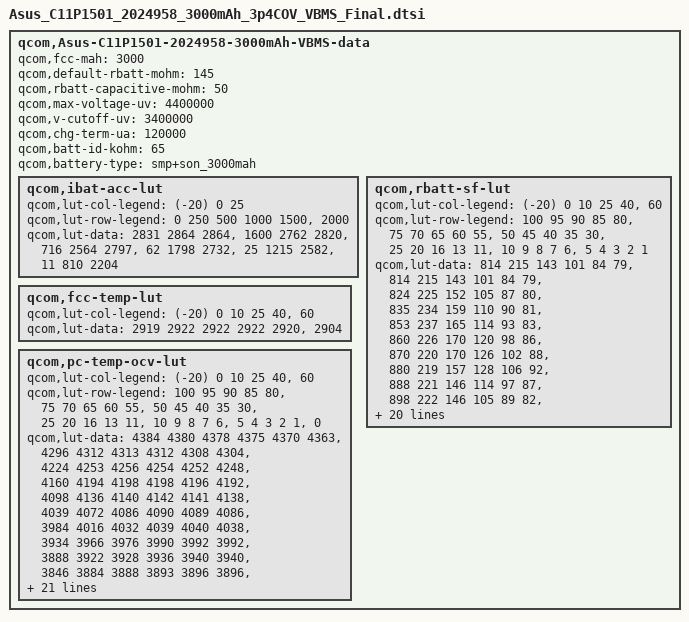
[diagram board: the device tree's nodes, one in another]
 qcom,Asus-C11P1501-2024958-3000mAh-VBMS-data {
	qcom,fcc-mah = <3000>;
	qcom,default-rbatt-mohm = <145>;
	qcom,rbatt-capacitive-mohm = <50>;
	qcom,max-voltage-uv = <4400000>;
	qcom,v-cutoff-uv = <3400000>;
	qcom,chg-term-ua = <120000>;
	qcom,batt-id-kohm = <65>;
	qcom,battery-type = "smp+son_3000mah";

	qcom,ibat-acc-lut {
		qcom,lut-col-legend = <(-20) 0 25>;
		qcom,lut-row-legend = <0 250 500 1000 1500>,
				<2000>;
		qcom,lut-data = <2831 2864 2864>,
				<1600 2762 2820>,
				<716 2564 2797>,
				<62 1798 2732>,
				<25 1215 2582>,
				<11 810 2204>;
	};

	qcom,rbatt-sf-lut {
		qcom,lut-col-legend = <(-20) 0 10 25 40>,
				<60>;
		qcom,lut-row-legend = <100 95 90 85 80>,
				<75 70 65 60 55>,
				<50 45 40 35 30>,
				<25 20 16 13 11>,
				<10 9 8 7 6>,
				<5 4 3 2 1>;
		qcom,lut-data = <814 215 143 101 84 79>,
				<814 215 143 101 84 79>,
				<824 225 152 105 87 80>,
				<835 234 159 110 90 81>,
				<853 237 165 114 93 83>,
				<860 226 170 120 98 86>,
				<870 220 170 126 102 88>,
				<880 219 157 128 106 92>,
				<888 221 146 114 97 87>,
				<898 222 146 105 89 82>,
				<919 226 149 103 88 81>,
				<953 230 152 107 90 82>,
				<1008 234 157 110 93 85>,
				<1088 243 160 114 96 87>,
				<1199 249 163 114 94 84>,
				<1356 255 166 110 91 82>,
				<1646 258 166 108 91 82>,
				<1948 258 161 109 90 83>,
				<2203 266 159 108 90 82>,
				<2425 284 163 109 91 83>,
				<2610 298 168 110 92 85>,
				<2849 313 174 113 94 88>,
				<2917 314 178 114 94 90>,
				<3444 324 183 117 95 91>,
				<5075 354 188 116 93 85>,
				<8561 406 192 113 92 85>,
				<16552 538 205 115 94 86>,
				<33105 989 243 121 97 88>,
				<63602 1978 328 130 102 91>,
				<100437 3956 657 157 126 106>;
	};

	qcom,fcc-temp-lut {
		qcom,lut-col-legend = <(-20) 0 10 25 40>,
				<60>;
		qcom,lut-data = <2919 2922 2922 2922 2920>,
				<2904>;
	};

	qcom,pc-temp-ocv-lut {
		qcom,lut-col-legend = <(-20) 0 10 25 40>,
				<60>;
		qcom,lut-row-legend = <100 95 90 85 80>,
				<75 70 65 60 55>,
				<50 45 40 35 30>,
				<25 20 16 13 11>,
				<10 9 8 7 6>,
				<5 4 3 2 1>,
				<0>;
		qcom,lut-data = <4384 4380 4378 4375 4370 4363>,
				<4296 4312 4313 4312 4308 4304>,
				<4224 4253 4256 4254 4252 4248>,
				<4160 4194 4198 4198 4196 4192>,
				<4098 4136 4140 4142 4141 4138>,
				<4039 4072 4086 4090 4089 4086>,
				<3984 4016 4032 4039 4040 4038>,
				<3934 3966 3976 3990 3992 3992>,
				<3888 3922 3928 3936 3940 3940>,
				<3846 3884 3888 3893 3896 3896>,
				<3809 3852 3856 3860 3862 3862>,
				<3779 3824 3830 3834 3836 3836>,
				<3755 3800 3806 3810 3814 3814>,
				<3736 3780 3786 3792 3794 3792>,
				<3718 3762 3768 3772 3770 3763>,
				<3702 3744 3750 3750 3744 3734>,
				<3686 3722 3728 3726 3720 3708>,
				<3670 3699 3704 3702 3696 3684>,
				<3654 3680 3684 3684 3678 3666>,
				<3638 3669 3672 3674 3670 3660>,
				<3628 3663 3668 3671 3667 3657>,
				<3617 3656 3662 3668 3664 3652>,
				<3604 3649 3657 3662 3658 3649>,
				<3590 3638 3648 3654 3648 3640>,
				<3568 3620 3628 3634 3626 3612>,
				<3535 3589 3594 3597 3588 3570>,
				<3488 3538 3542 3546 3536 3516>,
				<3418 3470 3474 3482 3471 3458>,
				<3320 3378 3386 3396 3384 3373>,
				<3188 3246 3258 3268 3254 3248>,
				<3000 3000 3000 3000 3000 3000>;
	};
};
